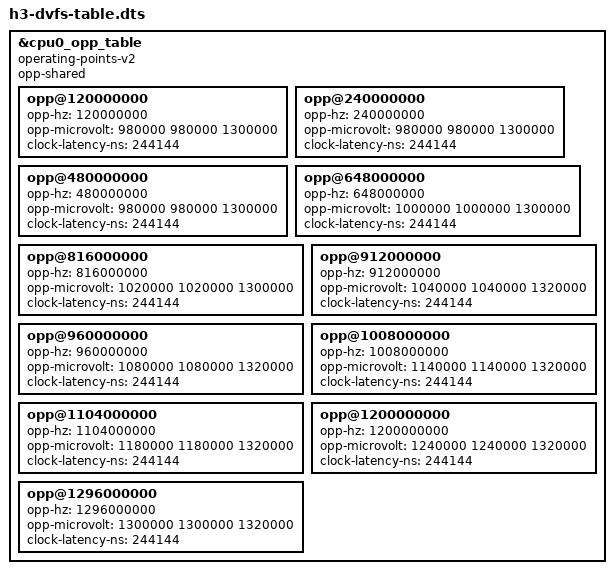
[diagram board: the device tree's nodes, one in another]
/dts-v1/;
/plugin/;

/ {
	fragment@0 {
		target = <&cpu0_opp_table>;

		__overlay__ {
			compatible = "operating-points-v2";
			opp-shared;

			opp@120000000 {
				opp-hz = /bits/ 64 <120000000>;
				opp-microvolt = <980000 980000 1300000>;
				clock-latency-ns = <244144>; /* 8 32k periods */
			};

			opp@240000000 {
				opp-hz = /bits/ 64 <240000000>;
				opp-microvolt = <980000 980000 1300000>;
				clock-latency-ns = <244144>; /* 8 32k periods */
			};

			opp@480000000 {
				opp-hz = /bits/ 64 <480000000>;
				opp-microvolt = <980000 980000 1300000>;
				clock-latency-ns = <244144>; /* 8 32k periods */
			};

			opp@648000000 {
				opp-hz = /bits/ 64 <648000000>;
				opp-microvolt = <1000000 1000000 1300000>;
				clock-latency-ns = <244144>; /* 8 32k periods */
			};

			opp@816000000 {
				opp-hz = /bits/ 64 <816000000>;
				opp-microvolt = <1020000 1020000 1300000>;
				clock-latency-ns = <244144>; /* 8 32k periods */
			};

			opp@912000000 {
				opp-hz = /bits/ 64 <912000000>;
				opp-microvolt = <1040000 1040000 1320000>;
				clock-latency-ns = <244144>; /* 8 32k periods */
			};

			opp@960000000 {
				opp-hz = /bits/ 64 <960000000>;
				opp-microvolt = <1080000 1080000 1320000>;
				clock-latency-ns = <244144>; /* 8 32k periods */
			};

			opp@1008000000 {
				opp-hz = /bits/ 64 <1008000000>;
				opp-microvolt = <1140000 1140000 1320000>;
				clock-latency-ns = <244144>; /* 8 32k periods */
			};

			opp@1104000000 {
				opp-hz = /bits/ 64 <1104000000>;
				opp-microvolt = <1180000 1180000 1320000>;
				clock-latency-ns = <244144>; /* 8 32k periods */
			};

			opp@1200000000 {
				opp-hz = /bits/ 64 <1200000000>;
				opp-microvolt = <1240000 1240000 1320000>;
				clock-latency-ns = <244144>; /* 8 32k periods */
			};

			opp@1296000000 {
				opp-hz = /bits/ 64 <1296000000>;
				opp-microvolt = <1300000 1300000 1320000>;
				clock-latency-ns = <244144>; /* 8 32k periods */
			};

		};
	};
};
